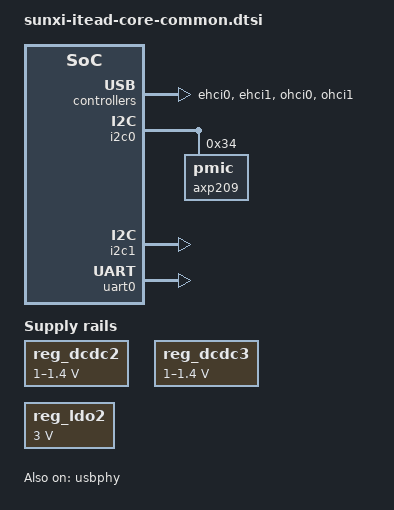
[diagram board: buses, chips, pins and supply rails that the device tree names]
#include "sunxi-common-regulators.dtsi"
/ {
	aliases {
		serial0 = &uart0;
	};
	chosen {
		stdout-path = "serial0:115200n8";
	};
};
&cpu0 {
	cpu-supply = <&reg_dcdc2>;
};
&ehci0 {
	status = "okay";
};
&ehci1 {
	status = "okay";
};
&i2c0 {
	status = "okay";
	axp209: pmic@34 {
		reg = <0x34>;
	};
};
&i2c1 {
	status = "okay";
};
&ohci0 {
	status = "okay";
};
&ohci1 {
	status = "okay";
};
#include "axp209.dtsi"
&reg_dcdc2 {
	regulator-always-on;
	regulator-min-microvolt = <1000000>;
	regulator-max-microvolt = <1400000>;
	regulator-name = "vdd-cpu";
};
&reg_dcdc3 {
	regulator-always-on;
	regulator-min-microvolt = <1000000>;
	regulator-max-microvolt = <1400000>;
	regulator-name = "vdd-int-dll";
};
&reg_ldo1 {
	regulator-name = "vdd-rtc";
};
&reg_ldo2 {
	regulator-always-on;
	regulator-min-microvolt = <3000000>;
	regulator-max-microvolt = <3000000>;
	regulator-name = "avcc";
};
&reg_usb1_vbus {
	status = "okay";
};
&reg_usb2_vbus {
	status = "okay";
};
&uart0 {
	pinctrl-names = "default";
	pinctrl-0 = <&uart0_pb_pins>;
	status = "okay";
};
&usbphy {
	usb1_vbus-supply = <&reg_usb1_vbus>;
	usb2_vbus-supply = <&reg_usb2_vbus>;
	status = "okay";
};
